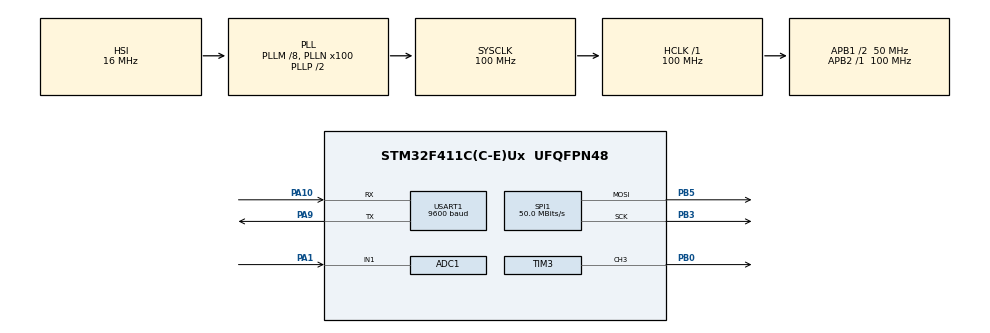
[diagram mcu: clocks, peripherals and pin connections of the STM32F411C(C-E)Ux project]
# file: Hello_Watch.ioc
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ADC1.Channel-3\#ChannelRegularConversion=ADC_CHANNEL_1
ADC1.NbrOfConversionFlag=1
ADC1.Rank-3\#ChannelRegularConversion=1
ADC1.SamplingTime-3\#ChannelRegularConversion=ADC_SAMPLETIME_3CYCLES
ADC1.master=1
Dma.Request0=USART1_RX
Dma.Request1=USART1_TX
Dma.Request2=SPI1_TX
Dma.SPI1_TX.2.Direction=DMA_MEMORY_TO_PERIPH
Dma.SPI1_TX.2.FIFOMode=DMA_FIFOMODE_DISABLE
Dma.SPI1_TX.2.Instance=DMA2_Stream2
Dma.SPI1_TX.2.MemDataAlignment=DMA_MDATAALIGN_HALFWORD
Dma.SPI1_TX.2.MemInc=DMA_MINC_ENABLE
Dma.SPI1_TX.2.Mode=DMA_NORMAL
Dma.SPI1_TX.2.PeriphDataAlignment=DMA_PDATAALIGN_HALFWORD
Dma.SPI1_TX.2.PeriphInc=DMA_PINC_DISABLE
Dma.SPI1_TX.2.Priority=DMA_PRIORITY_LOW
Dma.USART1_RX.0.Direction=DMA_PERIPH_TO_MEMORY
Dma.USART1_RX.0.FIFOMode=DMA_FIFOMODE_DISABLE
Dma.USART1_RX.0.Instance=DMA2_Stream5
Dma.USART1_RX.0.MemDataAlignment=DMA_MDATAALIGN_BYTE
Dma.USART1_RX.0.MemInc=DMA_MINC_ENABLE
Dma.USART1_RX.0.Mode=DMA_NORMAL
Dma.USART1_RX.0.PeriphDataAlignment=DMA_PDATAALIGN_BYTE
Dma.USART1_RX.0.PeriphInc=DMA_PINC_DISABLE
Dma.USART1_RX.0.Priority=DMA_PRIORITY_LOW
Dma.USART1_TX.1.Direction=DMA_MEMORY_TO_PERIPH
Dma.USART1_TX.1.FIFOMode=DMA_FIFOMODE_DISABLE
Dma.USART1_TX.1.Instance=DMA2_Stream7
Dma.USART1_TX.1.MemDataAlignment=DMA_MDATAALIGN_BYTE
Dma.USART1_TX.1.MemInc=DMA_MINC_ENABLE
Dma.USART1_TX.1.Mode=DMA_NORMAL
Dma.USART1_TX.1.PeriphDataAlignment=DMA_PDATAALIGN_BYTE
Dma.USART1_TX.1.PeriphInc=DMA_PINC_DISABLE
Dma.USART1_TX.1.Priority=DMA_PRIORITY_LOW
FREERTOS.Tasks01=defaultTask,24,128,StartDefaultTask,Default,NULL,Dynamic,NULL,NULL
Mcu.Family=STM32F4
Mcu.Name=STM32F411C(C-E)Ux
Mcu.Package=UFQFPN48
NVIC.DMA2_Stream2_IRQn=true\:5\:0\:false\:false\:true\:true\:false\:true\:true
NVIC.DMA2_Stream5_IRQn=true\:5\:0\:true\:false\:true\:true\:false\:true\:true
NVIC.DMA2_Stream7_IRQn=true\:5\:0\:true\:false\:true\:true\:false\:true\:true
NVIC.PriorityGroup=NVIC_PRIORITYGROUP_4
NVIC.RTC_WKUP_IRQn=true\:5\:0\:true\:false\:true\:true\:true\:true\:true
NVIC.TIM1_UP_TIM10_IRQn=true\:15\:0\:false\:false\:true\:false\:false\:true\:true
NVIC.TimeBase=TIM1_UP_TIM10_IRQn
NVIC.TimeBaseIP=TIM1
NVIC.USART1_IRQn=true\:5\:0\:true\:false\:true\:true\:false\:true\:true
PA1.Signal=ADCx_IN1
PA10.Mode=Asynchronous
PA10.Signal=USART1_RX
PA13.Mode=Serial_Wire
PA13.Signal=SYS_JTMS-SWDIO
PA14.Mode=Serial_Wire
PA14.Signal=SYS_JTCK-SWCLK
PA9.Mode=Asynchronous
PA9.Signal=USART1_TX
PB0.Signal=S_TIM3_CH3
PB3.Mode=TX_Only_Simplex_Unidirect_Master
PB3.Signal=SPI1_SCK
PB5.Mode=TX_Only_Simplex_Unidirect_Master
PB5.Signal=SPI1_MOSI
PC14-OSC32_IN.Mode=LSE-External-Oscillator
PC14-OSC32_IN.Signal=RCC_OSC32_IN
PC15-OSC32_OUT.Mode=LSE-External-Oscillator
PC15-OSC32_OUT.Signal=RCC_OSC32_OUT
ProjectManager.HeapSize=0x200
ProjectManager.StackSize=0x400
ProjectManager.TargetToolchain=MDK-ARM V5.32
RCC.48MHZClocksFreq_Value=50000000
RCC.AHBFreq_Value=100000000
RCC.APB1CLKDivider=RCC_HCLK_DIV2
RCC.APB1Freq_Value=50000000
RCC.APB1TimFreq_Value=100000000
RCC.APB2Freq_Value=100000000
RCC.APB2TimFreq_Value=100000000
RCC.CortexFreq_Value=100000000
RCC.HCLKFreq_Value=100000000
RCC.HSE_VALUE=25000000
RCC.HSI_VALUE=16000000
RCC.PLLM=8
RCC.PLLN=100
RCC.RCC_RTC_Clock_Source=RCC_RTCCLKSOURCE_LSE
RCC.SYSCLKFreq_VALUE=100000000
RCC.SYSCLKSource=RCC_SYSCLKSOURCE_PLLCLK
RCC.VCOOutputFreq_Value=200000000
SH.ADCx_IN1.0=ADC1_IN1,IN1
SH.S_TIM3_CH3.0=TIM3_CH3,PWM Generation3 CH3
SPI1.CalculateBaudRate=50.0 MBits/s
SPI1.Direction=SPI_DIRECTION_2LINES
SPI1.Mode=SPI_MODE_MASTER
SPI1.VirtualType=VM_MASTER
TIM3.Channel-PWM\ Generation3\ CH3=TIM_CHANNEL_3
TIM3.Period=300
TIM3.Prescaler=99
USART1.BaudRate=9600
USART1.VirtualMode=VM_ASYNC
VP_FREERTOS_VS_CMSIS_V2.Mode=CMSIS_V2
VP_RTC_VS_RTC_Activate.Mode=RTC_Enabled
VP_RTC_VS_RTC_Calendar.Mode=RTC_Calendar
VP_RTC_VS_RTC_WakeUp_intern.Mode=WakeUp
VP_SYS_VS_tim1.Mode=TIM1
board=custom

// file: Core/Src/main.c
/* USER CODE BEGIN Header */
/**
  ******************************************************************************
  * @file           : main.c
  * @brief          : Main program body
  ******************************************************************************
  * @attention
  *
  * Copyright (c) 2025 STMicroelectronics.
  * All rights reserved.
  *
  * This software is licensed under terms that can be found in the LICENSE file
  * in the root directory of this software component.
  * If no LICENSE file comes with this software, it is provided AS-IS.
  *
  ******************************************************************************
  */
/* USER CODE END Header */
#include "main.h"
#include "cmsis_os.h"
#include "adc.h"
#include "dma.h"
#include "rtc.h"
#include "spi.h"
#include "tim.h"
#include "usart.h"
#include "gpio.h"

void SystemClock_Config(void);
void MX_FREERTOS_Init(void);

int main(void)
{

  /* USER CODE BEGIN 1 */
	//this must set same as keil setting
	SCB->VTOR = 0x0000C000U;
  /* USER CODE END 1 */

  /* MCU Configuration--------------------------------------------------------*/

  /* Reset of all peripherals, Initializes the Flash interface and the Systick. */
  HAL_Init();

  /* Configure the system clock */
  SystemClock_Config();

  /* USER CODE BEGIN SysInit */
   __enable_irq();
  /* USER CODE END SysInit */

  /* Initialize all configured peripherals */
  MX_GPIO_Init();
  MX_DMA_Init();
  MX_RTC_Init();
  MX_USART1_UART_Init();
  MX_ADC1_Init();
  MX_SPI1_Init();
  MX_TIM3_Init();

  /* Init scheduler */
  osKernelInitialize();  /* Call init function for freertos objects (in cmsis_os2.c) */
  MX_FREERTOS_Init();

  /* Start scheduler */
  osKernelStart();

  /* We should never get here as control is now taken by the scheduler */

  /* Infinite loop */
  while (1)
  {

  }
}

void SystemClock_Config(void)
{
  RCC_OscInitTypeDef RCC_OscInitStruct = {0};
  RCC_ClkInitTypeDef RCC_ClkInitStruct = {0};

  /** Configure the main internal regulator output voltage
  */
  __HAL_RCC_PWR_CLK_ENABLE();
  __HAL_PWR_VOLTAGESCALING_CONFIG(PWR_REGULATOR_VOLTAGE_SCALE1);

  /** Initializes the RCC Oscillators according to the specified parameters
  * in the RCC_OscInitTypeDef structure.
  */
  RCC_OscInitStruct.OscillatorType = RCC_OSCILLATORTYPE_HSI|RCC_OSCILLATORTYPE_LSE;
  RCC_OscInitStruct.LSEState = RCC_LSE_ON;
  RCC_OscInitStruct.HSIState = RCC_HSI_ON;
  RCC_OscInitStruct.HSICalibrationValue = RCC_HSICALIBRATION_DEFAULT;
  RCC_OscInitStruct.PLL.PLLState = RCC_PLL_ON;
  RCC_OscInitStruct.PLL.PLLSource = RCC_PLLSOURCE_HSI;
  RCC_OscInitStruct.PLL.PLLM = 8;
  RCC_OscInitStruct.PLL.PLLN = 100;
  RCC_OscInitStruct.PLL.PLLP = RCC_PLLP_DIV2;
  RCC_OscInitStruct.PLL.PLLQ = 4;
  if (HAL_RCC_OscConfig(&RCC_OscInitStruct) != HAL_OK)
  {
    Error_Handler();
  }

  /** Initializes the CPU, AHB and APB buses clocks
  */
  RCC_ClkInitStruct.ClockType = RCC_CLOCKTYPE_HCLK|RCC_CLOCKTYPE_SYSCLK
                              |RCC_CLOCKTYPE_PCLK1|RCC_CLOCKTYPE_PCLK2;
  RCC_ClkInitStruct.SYSCLKSource = RCC_SYSCLKSOURCE_PLLCLK;
  RCC_ClkInitStruct.AHBCLKDivider = RCC_SYSCLK_DIV1;
  RCC_ClkInitStruct.APB1CLKDivider = RCC_HCLK_DIV2;
  RCC_ClkInitStruct.APB2CLKDivider = RCC_HCLK_DIV1;

  if (HAL_RCC_ClockConfig(&RCC_ClkInitStruct, FLASH_LATENCY_3) != HAL_OK)
  {
    Error_Handler();
  }
}

void HAL_TIM_PeriodElapsedCallback(TIM_HandleTypeDef *htim)
{
  if (htim->Instance == TIM1)
  {
    HAL_IncTick();
  }
}

void Error_Handler(void)
{
  __disable_irq();
  while (1)
  {
  }
}

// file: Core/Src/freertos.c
/* USER CODE BEGIN Header */
/**
  ******************************************************************************
  * File Name          : freertos.c
  * Description        : Code for freertos applications
  ******************************************************************************
  * @attention
  *
  * Copyright (c) 2025 STMicroelectronics.
  * All rights reserved.
  *
  * This software is licensed under terms that can be found in the LICENSE file
  * in the root directory of this software component.
  * If no LICENSE file comes with this software, it is provided AS-IS.
  *
  ******************************************************************************
  */
/* USER CODE END Header */

#include "FreeRTOS.h"
#include "task.h"
#include "main.h"
#include "cmsis_os.h"

/* USER CODE BEGIN Includes */
#include "user_TasksInit.h"
/* USER CODE END Includes */

/* Definitions for defaultTask */
osThreadId_t defaultTaskHandle;
const osThreadAttr_t defaultTask_attributes = {
  .name = "defaultTask",
  .stack_size = 128 * 4,
  .priority = (osPriority_t) osPriorityNormal,
};

void StartDefaultTask(void *argument);

void MX_FREERTOS_Init(void); /* (MISRA C 2004 rule 8.1) */

/* Hook prototypes */
void vApplicationIdleHook(void);
void vApplicationTickHook(void);

/* USER CODE BEGIN 2 */
void vApplicationIdleHook( void )
{
   /* vApplicationIdleHook() will only be called if configUSE_IDLE_HOOK is set
   to 1 in FreeRTOSConfig.h. It will be called on each iteration of the idle
   task. It is essential that code added to this hook function never attempts
   to block in any way (for example, call xQueueReceive() with a block time
   specified, or call vTaskDelay()). If the application makes use of the
   vTaskDelete() API function (as this demo application does) then it is also
   important that vApplicationIdleHook() is permitted to return to its calling
   function, because it is the responsibility of the idle task to clean up
   memory allocated by the kernel to any task that has since been deleted. */
}
/* USER CODE END 2 */

/* USER CODE BEGIN 3 */
void vApplicationTickHook( void )
{
   /* This function will be called by each tick interrupt if
   configUSE_TICK_HOOK is set to 1 in FreeRTOSConfig.h. User code can be
   added here, but the tick hook is called from an interrupt context, so
   code must not attempt to block, and only the interrupt safe FreeRTOS API
   functions can be used (those that end in FromISR()). */
	TaskTickHook();
}
void MX_FREERTOS_Init(void) {
  /* USER CODE BEGIN Init */
	User_Tasks_Init();
  /* USER CODE END Init */

  /* Create the thread(s) */
  /* creation of defaultTask */
  defaultTaskHandle = osThreadNew(StartDefaultTask, NULL, &defaultTask_attributes);

}

void StartDefaultTask(void *argument)
{
  /* USER CODE BEGIN StartDefaultTask */
  /* Infinite loop */
  for(;;)
  {
   	HAL_GPIO_TogglePin(GPIOC, GPIO_PIN_13);
    osDelay(500);
  }
  /* USER CODE END StartDefaultTask */
}
